# CY8C5888LTI_LP097 register map
File version: 0.1
CY8C58LP
Registers are 8-bit, read-write, no defined reset value unless marked. A register's access mark holds for its fields unless they carry their own. Offsets are from the block's base; lines under a group give offsets from that group; [hi:lo] are bit positions; {n}, {i} and the like mark numbered series; 'fields as' and 'values as' point back to an identical list; <NAME> marks a mode.

## Memory map
0x00000000 Sample_Hold_1
0x00000000 ADC_DelSig_1
0x00000000 PWM_1
0x00000000 Motor_Reg_1
0x00000000 Motor_Reg_2
0x00000000 UART
0x00000000 I2C
0x00000000 Motor_Timer

## PWM_1
Base 0x00000000
0x4000642D PWM_1__COMPARE1 — UDB.D0 - Assigned Compare1 Value
0x4000643D PWM_1__COMPARE2 — UDB.D1 - Assigned Compare2 Value
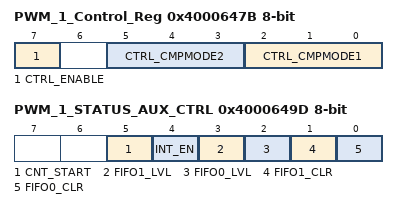
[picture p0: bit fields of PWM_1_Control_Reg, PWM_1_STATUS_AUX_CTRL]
0x4000647B PWM_1_Control_Reg — UDB Control Register - Assigned Control Register Value
  [7] CTRL_ENABLE — Enable the PWM
  [5:3] CTRL_CMPMODE2 — Compare mode 2
  [2:0] CTRL_CMPMODE1 — Compare mode 1
0x4000649D PWM_1_STATUS_AUX_CTRL — UDB Auxilliary Control Register
  [5] CNT_START — FIFO0 clear
    0=E_CNT_START0 (Disable counter); 1=E_CNT_START1 (Enable counter)
  [4] INT_EN
    0=E_INT_EN0 (Interrupt disabled); 1=E_INT_EN1 (Interrupt enabled)
  [3] FIFO1_LVL — FIFO level
    0=E_FIFO_LVL_0 (FIFO LVL: input mode: FIFO not full; output mode: FIFO not empty); 1=E_FIFO_LVL_1 (FIFO LVL: input mode: FIFO at least 1/2 empty; output mode: FIFO at least 1/2 full)
  [2] FIFO0_LVL — FIFO level
    values as FIFO1_LVL
  [1] FIFO1_CLR — FIFO1 clear
    0=E_FIFO_CLR_0 (Normal FIFO operation); 1=E_FIFO_CLR_1 (Clear FIFO state)
  [0] FIFO0_CLR — FIFO0 clear
    values as FIFO1_CLR

## Motor_Reg_1
Base 0x00000000
0x4000647D Motor_Reg_1_CONTROL_REG

## Motor_Reg_2
Base 0x00000000
0x4000657A Motor_Reg_2_CONTROL_REG

## UART
Base 0x00000000
0x40006429 RX_UART_RX_ADDRESS1 — RX Address1 Register
0x40006439 RX_UART_RX_ADDRESS2 — RX Address2 Register
0x40006449 RX_UART_RX_DATA — RX Data Register
0x4000644C TX_UART_TX_DATA — TX Data Register
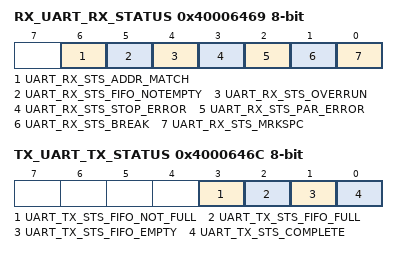
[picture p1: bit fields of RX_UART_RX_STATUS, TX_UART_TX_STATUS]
0x40006469 RX_UART_RX_STATUS — RX status register
  [6] UART_RX_STS_ADDR_MATCH ro, [5] UART_RX_STS_FIFO_NOTEMPTY ro, [4] UART_RX_STS_OVERRUN ro, [3] UART_RX_STS_STOP_ERROR ro, [2] UART_RX_STS_PAR_ERROR ro, [1] UART_RX_STS_BREAK ro, [0] UART_RX_STS_MRKSPC ro
0x4000646C TX_UART_TX_STATUS — TX status register
  [3] UART_TX_STS_FIFO_NOT_FULL ro, [2] UART_TX_STS_FIFO_FULL ro, [1] UART_TX_STS_FIFO_EMPTY ro, [0] UART_TX_STS_COMPLETE ro

## I2C
Base 0x00000000
0x40006504 I2C_DATA
  [7:0] data — Read received data or write data to transmit. These bits are held zero if I2C_CFG.en_mstr and I2C_CFG.en_slave are both zero.
0x40006524 I2C_ADDR — I2C Slave Adddress Register
  [6:0] slave_address — These seven bits hold the slave's own device address.
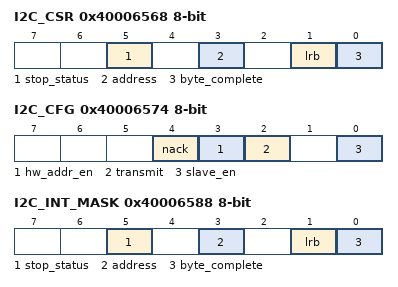
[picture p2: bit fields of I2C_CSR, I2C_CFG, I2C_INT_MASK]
0x40006568 I2C_CSR — I2C Status Register
  [5] stop_status ro — If set, indicates a Stop condition was detected on the bus.
  [3] address ro — Address detection. If set, indicates that an address byte was sent.
  [1] lrb ro — Last Received Bit. Indicates the state of the last received bit, which is the ACK/NAK received for the last byte transmitted. Cleared = ACK and set = NAK.
  [0] byte_complete ro — Transmit or receive status since the last read of this register. In Transmit mode this bit indicates that eight bits of data plus ACK/NAK have been transmitted since the last read. In Receive mode this bit indicates that eight bits of data have been received since the last read of this register.
0x40006574 I2C_CFG — I2C Configuration Register
  [4] nack — If set, used to NAK the last byte received. This bit must be cleared by firmware between bytes.
  [3] hw_addr_en — If set, used to enable the device to respond any device addresses it receives rather than just the single address provided in I2C_ADDRESS.
  [2] transmit — Used to set the mode to transmit or receive data. This bit must be cleared by firmware between bytes. Set = transmit and cleared = receive.
  [0] slave_en — Set to 1 to enable the slave functionality.
0x40006588 I2C_INT_MASK — I2C Interrupt Enable Mask
  [5] stop_status — Enables interrupt from the corresponding bit in status register.
  [3] address — Enables interrupt from the corresponding bit in status register.
  [1] lrb — Enables interrupt from the corresponding bit in status register.
  [0] byte_complete — Enables interrupt from the corresponding bit in status register.
